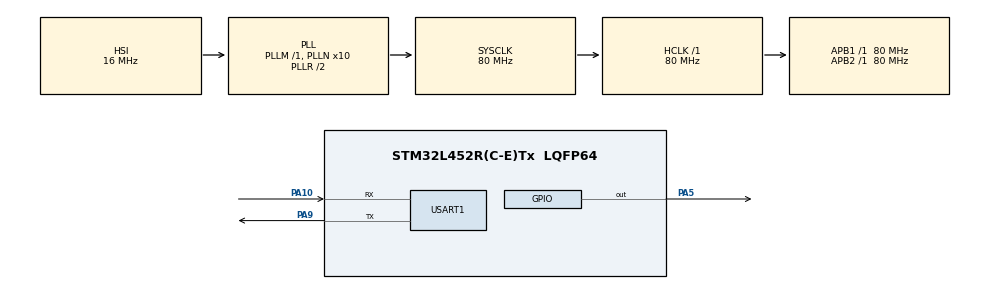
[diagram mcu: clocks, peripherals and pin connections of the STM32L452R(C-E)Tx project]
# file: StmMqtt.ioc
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Mcu.Family=STM32L4
Mcu.Name=STM32L452R(C-E)Tx
Mcu.Package=LQFP64
NVIC.PriorityGroup=NVIC_PRIORITYGROUP_4
NVIC.USART1_IRQn=true\:0\:0\:false\:false\:true\:true\:true\:true
PA10.Mode=Asynchronous
PA10.Signal=USART1_RX
PA13\ (JTMS/SWDIO).Mode=Serial_Wire
PA13\ (JTMS/SWDIO).Signal=SYS_JTMS-SWDIO
PA14\ (JTCK/SWCLK).Mode=Serial_Wire
PA14\ (JTCK/SWCLK).Signal=SYS_JTCK-SWCLK
PA5.Signal=GPIO_Output
PA9.Mode=Asynchronous
PA9.Signal=USART1_TX
PH0-OSC_IN\ (PH0).Mode=HSE-External-Oscillator
PH0-OSC_IN\ (PH0).Signal=RCC_OSC_IN
PH1-OSC_OUT\ (PH1).Mode=HSE-External-Oscillator
PH1-OSC_OUT\ (PH1).Signal=RCC_OSC_OUT
ProjectManager.HeapSize=0x200
ProjectManager.StackSize=0x400
ProjectManager.TargetToolchain=STM32CubeIDE
RCC.ADCFreq_Value=64000000
RCC.AHBFreq_Value=80000000
RCC.APB1Freq_Value=80000000
RCC.APB1TimFreq_Value=80000000
RCC.APB2Freq_Value=80000000
RCC.APB2TimFreq_Value=80000000
RCC.CortexFreq_Value=80000000
RCC.HCLKFreq_Value=80000000
RCC.HSE_VALUE=8000000
RCC.HSI48_VALUE=48000000
RCC.HSI_VALUE=16000000
RCC.LSE_VALUE=32768
RCC.MSI_VALUE=4000000
RCC.PLLN=10
RCC.PLLSourceVirtual=RCC_PLLSOURCE_HSI
RCC.PREFETCH_ENABLE=1
RCC.SYSCLKFreq_VALUE=80000000
RCC.SYSCLKSource=RCC_SYSCLKSOURCE_PLLCLK
RCC.USBFreq_Value=64000000
RCC.VCOOutputFreq_Value=160000000
USART1.VirtualMode-Asynchronous=VM_ASYNC
board=NUCLEO-L452RE

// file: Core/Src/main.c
/**
  ******************************************************************************
  * @file    main.c
  * @brief   Main program body
  ******************************************************************************
  * @attention
  *
  * Copyright (c) 2024 STMicroelectronics.
  * All rights reserved.
  *
  * This software is licensed under terms that can be found in the LICENSE file
  * in the root directory of this software component.
  * If no LICENSE file comes with this software, it is provided AS-IS.
  *
  ******************************************************************************
  */

#include "main.h"

/* USER CODE BEGIN Includes */
#include "esp8266.h"
#include "stm_mqtt.h"
#include <string.h>
/* USER CODE END Includes */

UART_HandleTypeDef huart1;

/* USER CODE BEGIN PV */

char received_topic[128];       /**< Topic of the received MQTT message */
char received_payload[128];     /**< Payload of the received MQTT message */
const char *subscribed_topic = "topic2"; /**< MQTT topic to subscribe */

/* USER CODE END PV */

void SystemClock_Config(void);
static void MX_GPIO_Init(void);
static void MX_USART1_UART_Init(void);

int main(void)
{

  /* MCU Configuration--------------------------------------------------------*/

  /* Reset of all peripherals, Initializes the Flash interface and the Systick. */
  HAL_Init();

  /* Configure the system clock */
  SystemClock_Config();

  /* Initialize all configured peripherals */
  MX_GPIO_Init();
  MX_USART1_UART_Init();

  /* Infinite loop */
  /* USER CODE BEGIN WHILE */
  bool b_mqtt_connected = false;   /**< Flag indicating MQTT connection status */
  bool b_mqtt_subscribed = false;  /**< Flag indicating MQTT subscription status */

  // Attempt to connect to Wi-Fi network and MQTT broker
  if (connect_to_network("DESKTOP-IBPU5MV 1627", "75S10m(1"))
  {
    if (stm_mqtt_connect("192.168.137.1", 1883, "client_01", 60))
    {
      b_mqtt_connected = true;

      // Subscribe to MQTT topic
      if (stm_mqtt_subscribe_qos0(subscribed_topic))
      {
        b_mqtt_subscribed = true;
      }
    }
  }

  int counter = 0;  /**< Counter variable for periodic tasks */

  while (1)
  {
    /* USER CODE END WHILE */

    /* USER CODE BEGIN 3 */
    if (b_mqtt_connected)
    {
      if (b_mqtt_subscribed)
      {
        // Clear received buffers
        memset(received_topic, 0, sizeof(received_topic));
        memset(received_payload, 0, sizeof(received_payload));

        // Parse received MQTT message
        if (stm_mqtt_parse_received_buffer(received_topic, received_payload))
        {
          // Check if received topic matches subscribed topic
          if (strcmp(received_topic, subscribed_topic) == 0)
          {
            // Control LED based on received payload
            if (strcmp(received_payload, "LED_ON") == 0)
            {
              HAL_GPIO_WritePin(GPIOA, GPIO_PIN_5, GPIO_PIN_SET);
            }
            else if (strcmp(received_payload, "LED_OFF") == 0)
            {
              HAL_GPIO_WritePin(GPIOA, GPIO_PIN_5, GPIO_PIN_RESET);
            }
          }
        }
      }

      // Publish MQTT message periodically
      if (HAL_GetTick() > counter + 999)
      {
        counter = HAL_GetTick();
        stm_mqtt_publish_qos0("topic1", "Hello from stm");
      }
    }
    /* USER CODE END 3 */
  }
  /* USER CODE END WHILE */
}

void SystemClock_Config(void)
{
  RCC_OscInitTypeDef RCC_OscInitStruct = {0};
  RCC_ClkInitTypeDef RCC_ClkInitStruct = {0};

  /** Configure the main internal regulator output voltage
  */
  if (HAL_PWREx_ControlVoltageScaling(PWR_REGULATOR_VOLTAGE_SCALE1) != HAL_OK)
  {
    Error_Handler();
  }

  /** Initializes the RCC Oscillators according to the specified parameters
  * in the RCC_OscInitTypeDef structure.
  */
  RCC_OscInitStruct.OscillatorType = RCC_OSCILLATORTYPE_HSI;
  RCC_OscInitStruct.HSIState = RCC_HSI_ON;
  RCC_OscInitStruct.HSICalibrationValue = 64;
  RCC_OscInitStruct.PLL.PLLState = RCC_PLL_ON;
  RCC_OscInitStruct.PLL.PLLSource = RCC_PLLSOURCE_HSI;
  RCC_OscInitStruct.PLL.PLLM = 1;
  RCC_OscInitStruct.PLL.PLLN = 10;
  RCC_OscInitStruct.PLL.PLLP = RCC_PLLP_DIV7;
  RCC_OscInitStruct.PLL.PLLQ = RCC_PLLQ_DIV2;
  RCC_OscInitStruct.PLL.PLLR = RCC_PLLR_DIV2;
  if (HAL_RCC_OscConfig(&RCC_OscInitStruct) != HAL_OK)
  {
    Error_Handler();
  }

  /** Initializes the CPU, AHB and APB buses clocks
  */
  RCC_ClkInitStruct.ClockType = RCC_CLOCKTYPE_HCLK|RCC_CLOCKTYPE_SYSCLK
                              |RCC_CLOCKTYPE_PCLK1|RCC_CLOCKTYPE_PCLK2;
  RCC_ClkInitStruct.SYSCLKSource = RCC_SYSCLKSOURCE_PLLCLK;
  RCC_ClkInitStruct.AHBCLKDivider = RCC_SYSCLK_DIV1;
  RCC_ClkInitStruct.APB1CLKDivider = RCC_HCLK_DIV1;
  RCC_ClkInitStruct.APB2CLKDivider = RCC_HCLK_DIV1;

  if (HAL_RCC_ClockConfig(&RCC_ClkInitStruct, FLASH_LATENCY_4) != HAL_OK)
  {
    Error_Handler();
  }
}

static void MX_USART1_UART_Init(void)
{

  huart1.Instance = USART1;
  huart1.Init.BaudRate = 115200;
  huart1.Init.WordLength = UART_WORDLENGTH_8B;
  huart1.Init.StopBits = UART_STOPBITS_1;
  huart1.Init.Parity = UART_PARITY_NONE;
  huart1.Init.Mode = UART_MODE_TX_RX;
  huart1.Init.HwFlowCtl = UART_HWCONTROL_NONE;
  huart1.Init.OverSampling = UART_OVERSAMPLING_16;
  huart1.Init.OneBitSampling = UART_ONE_BIT_SAMPLE_DISABLE;
  huart1.AdvancedInit.AdvFeatureInit = UART_ADVFEATURE_NO_INIT;
  if (HAL_UART_Init(&huart1) != HAL_OK)
  {
    Error_Handler();
  }

}

static void MX_GPIO_Init(void)
{
  GPIO_InitTypeDef GPIO_InitStruct = {0};

  /* GPIO Ports Clock Enable */
  __HAL_RCC_GPIOH_CLK_ENABLE();
  __HAL_RCC_GPIOA_CLK_ENABLE();

  /*Configure GPIO pin Output Level */
  HAL_GPIO_WritePin(GPIOA, GPIO_PIN_5, GPIO_PIN_RESET);

  /*Configure GPIO pin : PA5 */
  GPIO_InitStruct.Pin = GPIO_PIN_5;
  GPIO_InitStruct.Mode = GPIO_MODE_OUTPUT_PP;
  GPIO_InitStruct.Pull = GPIO_NOPULL;
  GPIO_InitStruct.Speed = GPIO_SPEED_FREQ_LOW;
  HAL_GPIO_Init(GPIOA, &GPIO_InitStruct);

}

void Error_Handler(void)
{
  __disable_irq();
  while (1)
  {
  }
}
